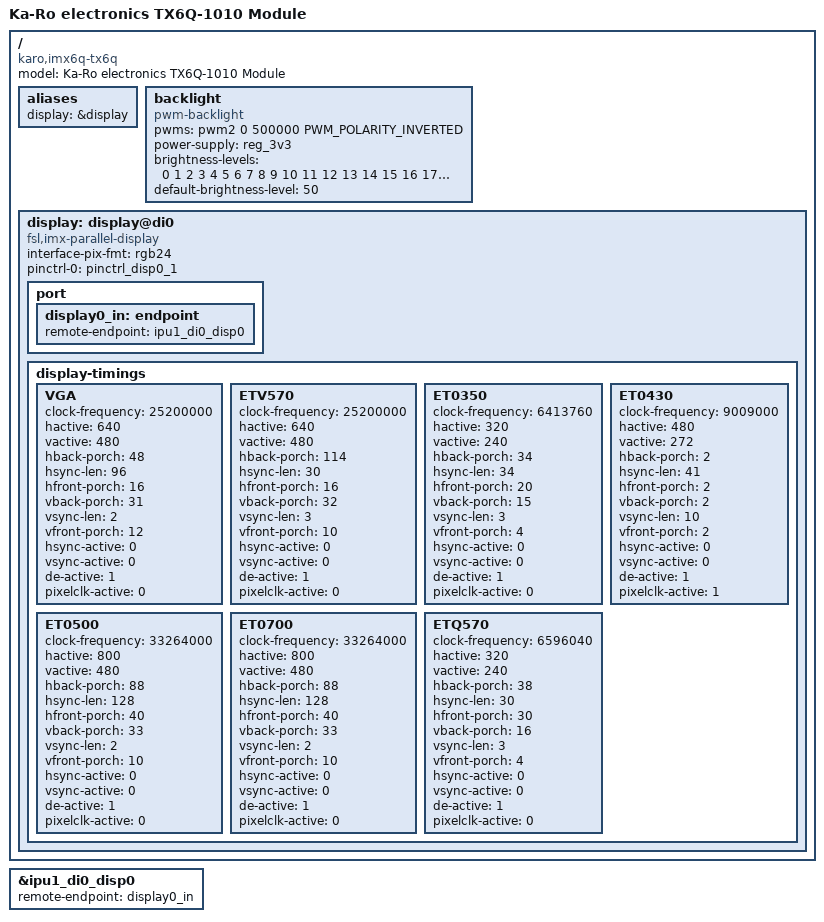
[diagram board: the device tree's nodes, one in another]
/*
 * Copyright 2014-2016 Lothar Waßmann <LW@KARO-electronics.de>
 *
 * This file is dual-licensed: you can use it either under the terms
 * of the GPL or the X11 license, at your option. Note that this dual
 * licensing only applies to this file, and not this project as a
 * whole.
 *
 *  a) This file is free software; you can redistribute it and/or
 *     modify it under the terms of the GNU General Public License
 *     version 2 as published by the Free Software Foundation.
 *
 *     This file is distributed in the hope that it will be useful,
 *     but WITHOUT ANY WARRANTY; without even the implied warranty of
 *     MERCHANTABILITY or FITNESS FOR A PARTICULAR PURPOSE.  See the
 *     GNU General Public License for more details.
 *
 * Or, alternatively,
 *
 *  b) Permission is hereby granted, free of charge, to any person
 *     obtaining a copy of this software and associated documentation
 *     files (the "Software"), to deal in the Software without
 *     restriction, including without limitation the rights to use,
 *     copy, modify, merge, publish, distribute, sublicense, and/or
 *     sell copies of the Software, and to permit persons to whom the
 *     Software is furnished to do so, subject to the following
 *     conditions:
 *
 *     The above copyright notice and this permission notice shall be
 *     included in all copies or substantial portions of the Software.
 *
 *     THE SOFTWARE IS PROVIDED "AS IS", WITHOUT WARRANTY OF ANY KIND,
 *     EXPRESS OR IMPLIED, INCLUDING BUT NOT LIMITED TO THE WARRANTIES
 *     OF MERCHANTABILITY, FITNESS FOR A PARTICULAR PURPOSE AND
 *     NONINFRINGEMENT. IN NO EVENT SHALL THE AUTHORS OR COPYRIGHT
 *     HOLDERS BE LIABLE FOR ANY CLAIM, DAMAGES OR OTHER LIABILITY,
 *     WHETHER IN AN ACTION OF CONTRACT, TORT OR OTHERWISE, ARISING
 *     FROM, OUT OF OR IN CONNECTION WITH THE SOFTWARE OR THE USE OR
 *     OTHER DEALINGS IN THE SOFTWARE.
 */

/dts-v1/;
#include "imx6q.dtsi"
#include "imx6qdl-tx6.dtsi"

/ {
	model = "Ka-Ro electronics TX6Q-1010 Module";
	compatible = "karo,imx6q-tx6q", "fsl,imx6q";

	aliases {
		display = &display;
	};

	backlight: backlight {
		compatible = "pwm-backlight";
		pwms = <&pwm2 0 500000 PWM_POLARITY_INVERTED>;
		power-supply = <&reg_3v3>;
		/*
		 * a poor man's way to create a 1:1 relationship between
		 * the PWM value and the actual duty cycle
		 */
		brightness-levels = < 0  1  2  3  4  5  6  7  8  9
				     10 11 12 13 14 15 16 17 18 19
				     20 21 22 23 24 25 26 27 28 29
				     30 31 32 33 34 35 36 37 38 39
				     40 41 42 43 44 45 46 47 48 49
				     50 51 52 53 54 55 56 57 58 59
				     60 61 62 63 64 65 66 67 68 69
				     70 71 72 73 74 75 76 77 78 79
				     80 81 82 83 84 85 86 87 88 89
				     90 91 92 93 94 95 96 97 98 99
				    100>;
		default-brightness-level = <50>;
	};

	display: display@di0 {
		compatible = "fsl,imx-parallel-display";
		interface-pix-fmt = "rgb24";
		pinctrl-names = "default";
		pinctrl-0 = <&pinctrl_disp0_1>;
		status = "okay";

		port {
			display0_in: endpoint {
				remote-endpoint = <&ipu1_di0_disp0>;
			};
		};

		display-timings {
			VGA {
				clock-frequency = <25200000>;
				hactive = <640>;
				vactive = <480>;
				hback-porch = <48>;
				hsync-len = <96>;
				hfront-porch = <16>;
				vback-porch = <31>;
				vsync-len = <2>;
				vfront-porch = <12>;
				hsync-active = <0>;
				vsync-active = <0>;
				de-active = <1>;
				pixelclk-active = <0>;
			};

			ETV570 {
				clock-frequency = <25200000>;
				hactive = <640>;
				vactive = <480>;
				hback-porch = <114>;
				hsync-len = <30>;
				hfront-porch = <16>;
				vback-porch = <32>;
				vsync-len = <3>;
				vfront-porch = <10>;
				hsync-active = <0>;
				vsync-active = <0>;
				de-active = <1>;
				pixelclk-active = <0>;
			};

			ET0350 {
				clock-frequency = <6413760>;
				hactive = <320>;
				vactive = <240>;
				hback-porch = <34>;
				hsync-len = <34>;
				hfront-porch = <20>;
				vback-porch = <15>;
				vsync-len = <3>;
				vfront-porch = <4>;
				hsync-active = <0>;
				vsync-active = <0>;
				de-active = <1>;
				pixelclk-active = <0>;
			};

			ET0430 {
				clock-frequency = <9009000>;
				hactive = <480>;
				vactive = <272>;
				hback-porch = <2>;
				hsync-len = <41>;
				hfront-porch = <2>;
				vback-porch = <2>;
				vsync-len = <10>;
				vfront-porch = <2>;
				hsync-active = <0>;
				vsync-active = <0>;
				de-active = <1>;
				pixelclk-active = <1>;
			};

			ET0500 {
				clock-frequency = <33264000>;
				hactive = <800>;
				vactive = <480>;
				hback-porch = <88>;
				hsync-len = <128>;
				hfront-porch = <40>;
				vback-porch = <33>;
				vsync-len = <2>;
				vfront-porch = <10>;
				hsync-active = <0>;
				vsync-active = <0>;
				de-active = <1>;
				pixelclk-active = <0>;
			};

			ET0700 { /* same as ET0500 */
				clock-frequency = <33264000>;
				hactive = <800>;
				vactive = <480>;
				hback-porch = <88>;
				hsync-len = <128>;
				hfront-porch = <40>;
				vback-porch = <33>;
				vsync-len = <2>;
				vfront-porch = <10>;
				hsync-active = <0>;
				vsync-active = <0>;
				de-active = <1>;
				pixelclk-active = <0>;
			};

			ETQ570 {
				clock-frequency = <6596040>;
				hactive = <320>;
				vactive = <240>;
				hback-porch = <38>;
				hsync-len = <30>;
				hfront-porch = <30>;
				vback-porch = <16>;
				vsync-len = <3>;
				vfront-porch = <4>;
				hsync-active = <0>;
				vsync-active = <0>;
				de-active = <1>;
				pixelclk-active = <0>;
			};
		};
        };
};

&ipu1_di0_disp0 {
	remote-endpoint = <&display0_in>;
};
